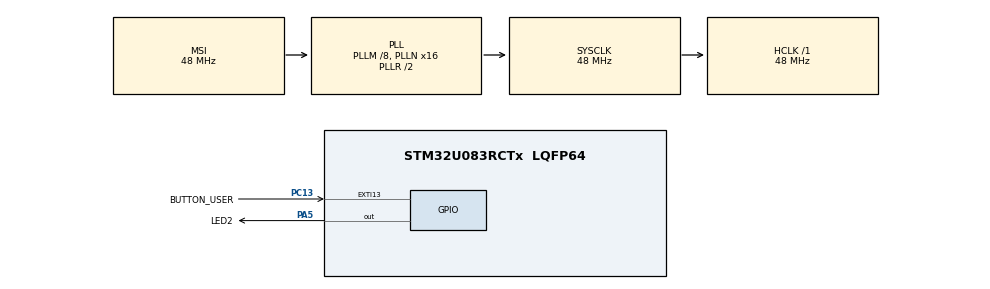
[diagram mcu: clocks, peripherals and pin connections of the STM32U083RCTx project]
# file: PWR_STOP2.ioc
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Mcu.Family=STM32U0
Mcu.Name=STM32U083RCTx
Mcu.Package=LQFP64
NVIC.EXTI4_15_IRQn=true\:0\:0\:false\:false\:true\:true\:true\:true
PA5.GPIO_Label=LED2
PA5.Signal=GPIO_Output
PC13.GPIO_Label=BUTTON_USER
PC13.GPIO_ModeDefaultEXTI=GPIO_MODE_IT_FALLING
PC13.GPIO_PuPd=GPIO_PULLUP
PC13.Signal=GPXTI13
ProjectManager.HeapSize=0x200
ProjectManager.StackSize=0x400
ProjectManager.TargetToolchain=EWARM V9.20
RCC.ADCFreq_Value=48000000
RCC.AHBFreq_Value=48000000
RCC.CortexFreq_Value=48000000
RCC.HCLKFreq_Value=48000000
RCC.HSE_VALUE=4000000
RCC.HSI48_VALUE=48000000
RCC.HSI_VALUE=16000000
RCC.LSE_VALUE=32768
RCC.MSIClockRangeVal=RCC_MSIRANGE_11
RCC.MSI_VALUE=48000000
RCC.PLLM=RCC_PLLM_DIV8
RCC.PLLN=16
RCC.PLLSourceVirtual=RCC_PLLSOURCE_MSI
RCC.SYSCLKFreq_VALUE=48000000
RCC.SYSCLKSource=RCC_SYSCLKSOURCE_PLLCLK
RCC.USBFreq_Value=48000000
RCC.VCOOutputFreq_Value=96000000
VP_PWR_VS_SECSignals.Mode=Security/Privilege
board=custom

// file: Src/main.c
/* USER CODE BEGIN Header */
/**
  ******************************************************************************
  * @file           : main.c
  * @brief          : Main program body
  ******************************************************************************
  * @attention
  *
  * Copyright (c) 2023 STMicroelectronics.
  * All rights reserved.
  *
  * This software is licensed under terms that can be found in the LICENSE file
  * in the root directory of this software component.
  * If no LICENSE file comes with this software, it is provided AS-IS.
  *
  ******************************************************************************
  */
/* USER CODE END Header */
#include "main.h"

/* USER CODE BEGIN Includes */
#include "stm32u0xx_nucleo.h"
/* USER CODE END Includes */

/* USER CODE BEGIN PV */
/* Private variables ---------------------------------------------------------*/
#define LED_TOGGLE_DELAY         100
static __IO uint32_t TimingDelay;
/* USER CODE END PV */

void SystemClock_Config(void);
static void MX_GPIO_Init(void);
/* USER CODE BEGIN PFP */
/* Private function prototypes -----------------------------------------------*/
static void SYSCLKConfig_STOP(void);

/* USER CODE END PFP */

int main(void)
{

  /* MCU Configuration--------------------------------------------------------*/

  /* Reset of all peripherals, Initializes the Flash interface and the Systick. */
  HAL_Init();

  /* Configure the system clock */
  SystemClock_Config();

  /* Initialize all configured peripherals */
  MX_GPIO_Init();
  /* USER CODE BEGIN 2 */

  /* Enable Power Clock */
  __HAL_RCC_PWR_CLK_ENABLE();

  /* USER CODE END 2 */

  /* Infinite loop */
  while (1)
  {

    /* USER CODE BEGIN 3 */
     /* Insert 5 second delay */
    HAL_Delay(5000);

    /* Turn off LED4 */
    BSP_LED_Off(LED4);

    /* Enter STOP 2 mode */
    HAL_PWREx_EnterSTOP2Mode(PWR_STOPENTRY_WFI);

   /* ... STOP 2 mode ... */

    /* Configure system clock after wake-up from STOP: enable HSE, PLL and select
    PLL as system clock source (HSE and PLL are disabled in STOP mode) */
    SYSCLKConfig_STOP();

  }
  /* USER CODE END 3 */
}

void SystemClock_Config(void)
{
  RCC_OscInitTypeDef RCC_OscInitStruct = {0};
  RCC_ClkInitTypeDef RCC_ClkInitStruct = {0};

  /** Configure the main internal regulator output voltage
  */
  HAL_PWREx_ControlVoltageScaling(PWR_REGULATOR_VOLTAGE_SCALE1);

  /** Initializes the RCC Oscillators according to the specified parameters
  * in the RCC_OscInitTypeDef structure.
  */
  RCC_OscInitStruct.OscillatorType = RCC_OSCILLATORTYPE_MSI;
  RCC_OscInitStruct.MSIState = RCC_MSI_ON;
  RCC_OscInitStruct.MSICalibrationValue = RCC_MSICALIBRATION_DEFAULT;
  RCC_OscInitStruct.MSIClockRange = RCC_MSIRANGE_11;
  RCC_OscInitStruct.PLL.PLLState = RCC_PLL_ON;
  RCC_OscInitStruct.PLL.PLLSource = RCC_PLLSOURCE_MSI;
  RCC_OscInitStruct.PLL.PLLM = RCC_PLLM_DIV8;
  RCC_OscInitStruct.PLL.PLLN = 16;
  RCC_OscInitStruct.PLL.PLLP = RCC_PLLP_DIV2;
  RCC_OscInitStruct.PLL.PLLQ = RCC_PLLQ_DIV2;
  RCC_OscInitStruct.PLL.PLLR = RCC_PLLR_DIV2;
  if (HAL_RCC_OscConfig(&RCC_OscInitStruct) != HAL_OK)
  {
    Error_Handler();
  }

  /** Initializes the CPU, AHB and APB buses clocks
  */
  RCC_ClkInitStruct.ClockType = RCC_CLOCKTYPE_HCLK|RCC_CLOCKTYPE_SYSCLK
                              |RCC_CLOCKTYPE_PCLK1;
  RCC_ClkInitStruct.SYSCLKSource = RCC_SYSCLKSOURCE_PLLCLK;
  RCC_ClkInitStruct.AHBCLKDivider = RCC_SYSCLK_DIV1;
  RCC_ClkInitStruct.APB1CLKDivider = RCC_HCLK_DIV1;

  if (HAL_RCC_ClockConfig(&RCC_ClkInitStruct, FLASH_LATENCY_1) != HAL_OK)
  {
    Error_Handler();
  }
}

static void MX_GPIO_Init(void)
{
  GPIO_InitTypeDef GPIO_InitStruct = {0};

  /* GPIO Ports Clock Enable */
  __HAL_RCC_GPIOC_CLK_ENABLE();
  __HAL_RCC_GPIOA_CLK_ENABLE();

  /*Configure GPIO pin Output Level */
  HAL_GPIO_WritePin(LED2_GPIO_Port, LED2_Pin, GPIO_PIN_RESET);

  /*Configure GPIO pin : BUTTON_USER_Pin */
  GPIO_InitStruct.Pin = BUTTON_USER_Pin;
  GPIO_InitStruct.Mode = GPIO_MODE_IT_FALLING;
  GPIO_InitStruct.Pull = GPIO_PULLUP;
  HAL_GPIO_Init(BUTTON_USER_GPIO_Port, &GPIO_InitStruct);

  /*Configure GPIO pin : LED2_Pin */
  GPIO_InitStruct.Pin = LED2_Pin;
  GPIO_InitStruct.Mode = GPIO_MODE_OUTPUT_PP;
  GPIO_InitStruct.Pull = GPIO_NOPULL;
  GPIO_InitStruct.Speed = GPIO_SPEED_FREQ_LOW;
  HAL_GPIO_Init(LED2_GPIO_Port, &GPIO_InitStruct);

  /* EXTI interrupt init*/
  HAL_NVIC_SetPriority(EXTI4_15_IRQn, 0, 0);
  HAL_NVIC_EnableIRQ(EXTI4_15_IRQn);

}

/* USER CODE BEGIN 4 */

/**
  * @brief  Configures system clock after wake-up from STOP: enable HSE, PLL
  *         and select PLL as system clock source.
  * @param  None
  * @retval None
  */
static void SYSCLKConfig_STOP(void)
{
  RCC_ClkInitTypeDef RCC_ClkInitStruct = {0};
  RCC_OscInitTypeDef RCC_OscInitStruct = {0};
  uint32_t pFLatency = 0;

  /* Enable Power Control clock */
  __HAL_RCC_PWR_CLK_ENABLE();

  /* Get the Oscillators configuration according to the internal RCC registers */
  HAL_RCC_GetOscConfig(&RCC_OscInitStruct);

  /* After wake-up from STOP reconfigure the system clock: Enable HSI and PLL */
  RCC_OscInitStruct.OscillatorType      = RCC_OSCILLATORTYPE_HSI;
  RCC_OscInitStruct.HSIState            = RCC_HSI_ON;
  RCC_OscInitStruct.HSICalibrationValue = RCC_HSICALIBRATION_DEFAULT;
  RCC_OscInitStruct.PLL.PLLState        = RCC_PLL_ON;
  if (HAL_RCC_OscConfig(&RCC_OscInitStruct) != HAL_OK)
  {
    Error_Handler();
  }

  /* Get the Clocks configuration according to the internal RCC registers */
  HAL_RCC_GetClockConfig(&RCC_ClkInitStruct, &pFLatency);

  /* Select PLL as system clock source and configure the HCLK, PCLK1 and PCLK2
     clocks dividers */
  RCC_ClkInitStruct.ClockType     = RCC_CLOCKTYPE_SYSCLK;
  RCC_ClkInitStruct.SYSCLKSource  = RCC_SYSCLKSOURCE_PLLCLK;
  if (HAL_RCC_ClockConfig(&RCC_ClkInitStruct, pFLatency) != HAL_OK)
  {
    Error_Handler();
  }
}

/**
  * @brief SYSTICK callback
  * @param None
  * @retval None
  */
void HAL_SYSTICK_Callback(void)
{

  if (TimingDelay != 0)
  {
    TimingDelay--;
  }
  else
  {
    /* Toggle LED4 */
    BSP_LED_Toggle(LED4);
    TimingDelay = LED_TOGGLE_DELAY;
  }
}

/**
  * @brief EXTI line detection callbacks
  * @param GPIO_Pin: Specifies the pins connected EXTI line
  * @retval None
  */
void HAL_GPIO_EXTI_Falling_Callback(uint16_t GPIO_Pin)
{
  if (GPIO_Pin == BUTTON_USER_PIN)
  {
    /* Reconfigure LED4 */
    BSP_LED_Init(LED4);
    /* Switch on LED4 */
    BSP_LED_On(LED4);
  }
}

/* USER CODE END 4 */

void Error_Handler(void)
{
  /* USER CODE BEGIN Error_Handler_Debug */
  /* User can add his own implementation to report the HAL error return state */
  /* Switch on LED4 */
  BSP_LED_On(LED4);
  while (1)
  {
  }
  /* USER CODE END Error_Handler_Debug */
}
